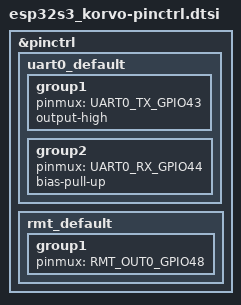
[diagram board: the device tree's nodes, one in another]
/*
 * SPDX-License-Identifier: Apache-2.0
 *
 * 引脚复用：把芯片的物理引脚映射到外设功能，并给出电气特性。
 * - uart0：控制台（IO43 / IO44）
 * - rmt  ：驱动板载 WS2812 的数据脚（IO48）
 */

#include <zephyr/dt-bindings/pinctrl/esp32s3-pinctrl.h>

&pinctrl {
	uart0_default: uart0_default {
		group1 {
			pinmux = <UART0_TX_GPIO43>;
			output-high;
		};

		group2 {
			pinmux = <UART0_RX_GPIO44>;
			bias-pull-up;
		};
	};

	rmt_default: rmt_default {
		group1 {
			pinmux = <RMT_OUT0_GPIO48>;
		};
	};
};
